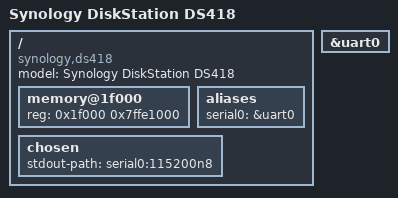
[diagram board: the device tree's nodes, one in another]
// SPDX-License-Identifier: (GPL-2.0-or-later OR BSD-2-Clause)
/*
 * Copyright (c) 2017-2019 Andreas Färber
 */

/dts-v1/;

#include "rtd1296.dtsi"

/ {
	compatible = "synology,ds418", "realtek,rtd1296";
	model = "Synology DiskStation DS418";

	memory@1f000 {
		device_type = "memory";
		reg = <0x1f000 0x7ffe1000>; /* boot ROM to 2 GiB */
	};

	aliases {
		serial0 = &uart0;
	};

	chosen {
		stdout-path = "serial0:115200n8";
	};
};

&uart0 {
	status = "okay";
};
